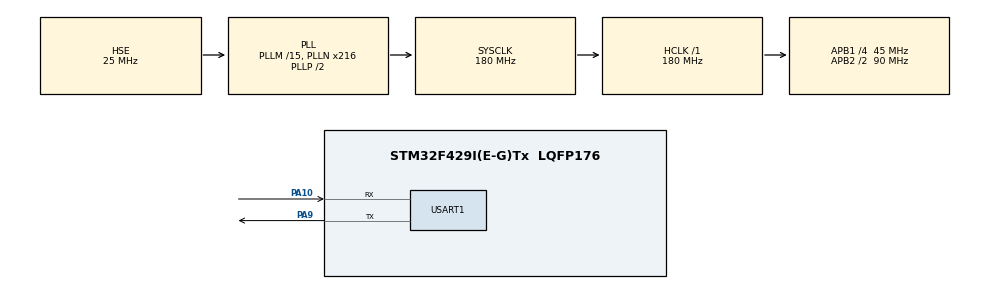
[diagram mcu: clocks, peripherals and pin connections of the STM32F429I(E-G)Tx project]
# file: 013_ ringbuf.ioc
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Mcu.Family=STM32F4
Mcu.Name=STM32F429I(E-G)Tx
Mcu.Package=LQFP176
NVIC.PriorityGroup=NVIC_PRIORITYGROUP_2
NVIC.USART1_IRQn=true\:1\:0\:true\:false\:true\:true\:true
PA10.Mode=Asynchronous
PA10.Signal=USART1_RX
PA13.Mode=Serial_Wire
PA13.Signal=SYS_JTMS-SWDIO
PA14.Mode=Serial_Wire
PA14.Signal=SYS_JTCK-SWCLK
PA9.Mode=Asynchronous
PA9.Signal=USART1_TX
PC14/OSC32_IN.Mode=LSE-External-Oscillator
PC14/OSC32_IN.Signal=RCC_OSC32_IN
PC15/OSC32_OUT.Mode=LSE-External-Oscillator
PC15/OSC32_OUT.Signal=RCC_OSC32_OUT
PH0/OSC_IN.Mode=HSE-External-Oscillator
PH0/OSC_IN.Signal=RCC_OSC_IN
PH1/OSC_OUT.Mode=HSE-External-Oscillator
PH1/OSC_OUT.Signal=RCC_OSC_OUT
ProjectManager.HeapSize=0x200
ProjectManager.StackSize=0x400
ProjectManager.TargetToolchain=MDK-ARM V5.27
RCC.48MHZClocksFreq_Value=90000000
RCC.AHBFreq_Value=180000000
RCC.APB1CLKDivider=RCC_HCLK_DIV4
RCC.APB1Freq_Value=45000000
RCC.APB1TimFreq_Value=90000000
RCC.APB2CLKDivider=RCC_HCLK_DIV2
RCC.APB2Freq_Value=90000000
RCC.APB2TimFreq_Value=180000000
RCC.CortexFreq_Value=180000000
RCC.HCLKFreq_Value=180000000
RCC.HSE_VALUE=25000000
RCC.HSI_VALUE=16000000
RCC.PLLM=15
RCC.PLLN=216
RCC.PLLSourceVirtual=RCC_PLLSOURCE_HSE
RCC.SYSCLKFreq_VALUE=180000000
RCC.SYSCLKSource=RCC_SYSCLKSOURCE_PLLCLK
RCC.VCOOutputFreq_Value=360000000
USART1.VirtualMode=VM_ASYNC
board=custom

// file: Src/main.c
/* USER CODE BEGIN Header */
/**
  ******************************************************************************
  * @file           : main.c
  * @brief          : Main program body
  ******************************************************************************
  * @attention
  *
  * <h2><center>&copy; Copyright (c) 2021 STMicroelectronics.
  * All rights reserved.</center></h2>
  *
  * This software component is licensed by ST under BSD 3-Clause license,
  * the "License"; You may not use this file except in compliance with the
  * License. You may obtain a copy of the License at:
  *                        opensource.org/licenses/BSD-3-Clause
  *
  ******************************************************************************
  */
/* USER CODE END Header */

#include "main.h"
#include "usart.h"
#include "gpio.h"

/* USER CODE BEGIN Includes */
#include "config.h"

/* USER CODE END Includes */

void SystemClock_Config(void);

/* USER CODE BEGIN 0 */

//开辟一块内存用于存放环形队列消息缓冲区
#define MSG_BUFFDATA_SIZE	128
static uint8_t msg_buffdata[MSG_BUFFDATA_SIZE];

//用于存储消息的环形缓冲队列的rt_ringbuffer句柄
struct rt_ringbuffer	msg_ringbuffer;

//系统消息处理
static uint8_t message_buff[256];
void msg_process(void)
{
	system_message sys_msg;

	if(rt_ringbuffer_data_len(&msg_ringbuffer)!= 0) //消息队列不为空，则有消息需要处理
	{
		rt_ringbuffer_get(&msg_ringbuffer,(uint8_t *) &sys_msg.msg_type, 2);//读取消息类型(1字节) + 消息参数(1字节)，其中：不同消息类型对应的消息参数意义也不同，由用户自行定义

		switch(sys_msg.msg_type)
		{
			case MSG_USART1_REC_FINISH:
				rt_ringbuffer_get(&usart1_recv_ring_buf, message_buff, sys_msg.msg_parameter);
			    message_buff[sys_msg.msg_parameter] = '\0';//sys_msg.msg_parameter中存放的是串口1接收帧的长度信息
			    printf("%s\n",message_buff);
				break;

			default:break;
		}
	}
}

/* USER CODE END 0 */

int main(void)
{

  /* MCU Configuration--------------------------------------------------------*/

  /* Reset of all peripherals, Initializes the Flash interface and the Systick. */
  HAL_Init();

  /* Configure the system clock */
  SystemClock_Config();

  /* Initialize all configured peripherals */
  MX_GPIO_Init();
  MX_USART1_UART_Init();
  /* USER CODE BEGIN 2 */
	printf("Test LwRB\r\n\t");

	//初始化消息环形队列
	rt_ringbuffer_init(&msg_ringbuffer, msg_buffdata, MSG_BUFFDATA_SIZE);

//	//使能串口中断接收
//	HAL_UART_Receive_IT(&huart1, (uint8_t*)&recv_data, 1);

  /* USER CODE END 2 */

  /* Infinite loop */
  /* USER CODE BEGIN WHILE */
  while (1)
  {
		HAL_Delay(200);
		msg_process();

	}
    /* USER CODE END WHILE */

}

void SystemClock_Config(void)
{
  RCC_OscInitTypeDef RCC_OscInitStruct = {0};
  RCC_ClkInitTypeDef RCC_ClkInitStruct = {0};

  /** Configure the main internal regulator output voltage
  */
  __HAL_RCC_PWR_CLK_ENABLE();
  __HAL_PWR_VOLTAGESCALING_CONFIG(PWR_REGULATOR_VOLTAGE_SCALE1);
  /** Initializes the CPU, AHB and APB busses clocks
  */
  RCC_OscInitStruct.OscillatorType = RCC_OSCILLATORTYPE_HSE;
  RCC_OscInitStruct.HSEState = RCC_HSE_ON;
  RCC_OscInitStruct.PLL.PLLState = RCC_PLL_ON;
  RCC_OscInitStruct.PLL.PLLSource = RCC_PLLSOURCE_HSE;
  RCC_OscInitStruct.PLL.PLLM = 15;
  RCC_OscInitStruct.PLL.PLLN = 216;
  RCC_OscInitStruct.PLL.PLLP = RCC_PLLP_DIV2;
  RCC_OscInitStruct.PLL.PLLQ = 4;
  if (HAL_RCC_OscConfig(&RCC_OscInitStruct) != HAL_OK)
  {
    Error_Handler();
  }
  /** Activate the Over-Drive mode
  */
  if (HAL_PWREx_EnableOverDrive() != HAL_OK)
  {
    Error_Handler();
  }
  /** Initializes the CPU, AHB and APB busses clocks
  */
  RCC_ClkInitStruct.ClockType = RCC_CLOCKTYPE_HCLK|RCC_CLOCKTYPE_SYSCLK
                              |RCC_CLOCKTYPE_PCLK1|RCC_CLOCKTYPE_PCLK2;
  RCC_ClkInitStruct.SYSCLKSource = RCC_SYSCLKSOURCE_PLLCLK;
  RCC_ClkInitStruct.AHBCLKDivider = RCC_SYSCLK_DIV1;
  RCC_ClkInitStruct.APB1CLKDivider = RCC_HCLK_DIV4;
  RCC_ClkInitStruct.APB2CLKDivider = RCC_HCLK_DIV2;

  if (HAL_RCC_ClockConfig(&RCC_ClkInitStruct, FLASH_LATENCY_5) != HAL_OK)
  {
    Error_Handler();
  }
}

void Error_Handler(void)
{
}

/************************ (C) COPYRIGHT STMicroelectronics *****END OF FILE****/
